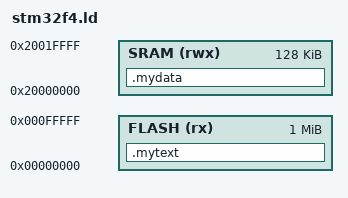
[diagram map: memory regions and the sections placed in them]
MEMORY
{
	FLASH (rx) : ORIGIN = 0x00000000, LENGTH = 1M
	SRAM (rwx) : ORIGIN = 0x20000000, LENGTH = 128K
}

SECTIONS
{
	.mytext :
	{
		KEEP(*(.vector_table))
		*(.text)
		_mydata = .;
	} > FLASH

	.mydata :	AT(_mydata)
	{
		*(.data)
	} > SRAM

}
